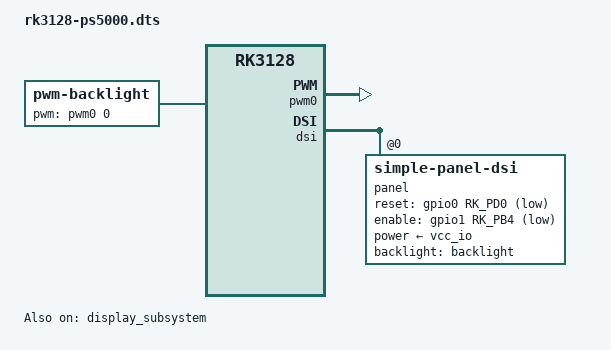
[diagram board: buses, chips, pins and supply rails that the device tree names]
/*
 * (C) Copyright 2021 Martin Cerveny
 *
 * SPDX-License-Identifier:     GPL-2.0+
 */

/dts-v1/;

#include "rk3128-wx8.dtsi"

/ {
	backlight: backlight {
		compatible = "pwm-backlight";
		pwms = <&pwm0 0 25000 0>;
		default-brightness-level = <200>;
		brightness-levels = <
			  0   1   2   3   4   5   6   7
			  8   9  10  11  12  13  14  15
			 16  17  18  19  20  21  22  23
			 24  25  26  27  28  29  30  31
			 32  33  34  35  36  37  38  39
			 40  41  42  43  44  45  46  47
			 48  49  50  51  52  53  54  55
			 56  57  58  59  60  61  62  63
			 64  65  66  67  68  69  70  71
			 72  73  74  75  76  77  78  79
			 80  81  82  83  84  85  86  87
			 88  89  90  91  92  93  94  95
			 96  97  98  99 100 101 102 103
			104 105 106 107 108 109 110 111
			112 113 114 115 116 117 118 119
			120 121 122 123 124 125 126 127
			128 129 130 131 132 133 134 135
			136 137 138 139 140 141 142 143
			144 145 146 147 148 149 150 151
			152 153 154 155 156 157 158 159
			160 161 162 163 164 165 166 167
			168 169 170 171 172 173 174 175
			176 177 178 179 180 181 182 183
			184 185 186 187 188 189 190 191
			192 193 194 195 196 197 198 199
			200 201 202 203 204 205 206 207
			208 209 210 211 212 213 214 215
			216 217 218 219 220 221 222 223
			224 225 226 227 228 229 230 231
			232 233 234 235 236 237 238 239
			240 241 242 243 244 245 246 247
			248 249 250 251 252 253 254 255>;
		status = "okay";
	};
};

&power_supply {
        discharge_table = <3500 3586 3636 3663 3724 3744 3760 3773 3772 3794 3806 3854 3897 3949 3986 4035 4075 4118 4150>;	// mV
        charge_table =    <3600 3900 3928 3965 3994 4015 4023 4045 4059 4096 4133 4171 4250>;	// mV, without mA cannot determine charging in CV part

        design_capacity = <3000>;	// mAh, battery "GSL475568"
};

&pwm0 {
	status = "okay";
};

&display_subsystem {
	status = "okay";
	logo-memory-region = <&drm_logo>;

	route {
		route_dsi: route-dsi {
			connect = <&vop_out_dsi>;
			status = "okay";
		};
		route_hdmi: route-hdmi {
			connect = <&vop_out_hdmi>;
			status = "okay";
		};
	};

};

&dsi {
	status = "okay";

	panel@0 {
		compatible = "simple-panel-dsi";
		reg = <0>;
		power-supply = <&vcc_io>;
		backlight = <&backlight>;
		pinctrl-names = "default";
		pinctrl-0 = <&lcd_reset &lcd_enable>;
		dsi,flags = <(MIPI_DSI_MODE_LPM | MIPI_DSI_MODE_EOT_PACKET | MIPI_DSI_MODE_VIDEO_BURST | MIPI_DSI_MODE_VIDEO)>;
		dsi,format = <MIPI_DSI_FMT_RGB888>;
		dsi,lanes = <2>;
		reset-gpios = <&gpio0 RK_PD0 GPIO_ACTIVE_LOW>;
		enable-gpios = <&gpio1 RK_PB4 GPIO_ACTIVE_LOW>;
		reset-delay-ms = <10>;
		enable-delay-ms = <100>;
		prepare-delay-ms = <10>;
		unprepare-delay-ms = <2000>;
		init-delay-ms = <1000>;
		panel-init-sequence = [
			39 00 03 f0 5a 5a
			39 00 06 a1 00 00 06 08 ff
			39 00 04 b1 07 00 00
			39 00 05 b2 11 11 11 11
			15 00 02 b3 01
			15 00 02 b4 15
			39 00 16 b5 ff ef 35 42 0d d7 ff 07 ff ff fd 00 01 ff 05 12 0f ff ff ff ff
			15 00 02 c0 00
			39 00 1d c1 00 4d 96 1d 00 00 0f 3b 00 00 0f 21 05 0a 0f 14 19 1e 23 28 2d 32 37 3c 41 46 4b 50
			39 00 05 f4 33 42 00 08
			39 00 06 f5 00 06 26 35 03
			15 00 02 f7 20
			39 00 15 f8 7f 7a 89 67 26 38 00 00 09 67 70 88 7a 76 05 09 23 23 23 00
			39 00 17 f9 00 9f 9f be cf d7 c9 c2 cb bb e1 e3 de d6 d0 d3 fa ed e6 2f 00 2f
			05 c8 01 11
			05 78 01 29
			15 00 02 35 00];
		panel-exit-sequence = <0x05000128 0x05000110>;

		display-timings {
			native-mode = <&timing0>;

			timing0: timing0 {
				clock-frequency = <33000000>;
				hactive = <960>;
				vactive = <544>;
				hback-porch = <15>;
				hfront-porch = <5>;
				hsync-len = <4>;
				vback-porch = <10>;
				vfront-porch = <10>;
				vsync-len = <4>;
				hsync-active = <0>;
				vsync-active = <0>;
				de-active = <0>;
				pixelclk-active = <0>;
			};
		};
	};
};
